# GENERAL register map
Vendor: Texas Instruments
Peripheral module from a debugger description file (folder omap36xx).
Registers are 32-bit, access per field, reset 0x0 unless marked. A register's access mark holds for its fields unless they carry their own. Offsets are as the file gives them; lines under a group give offsets from that group; [hi:lo] are bit positions; {n}, {i} and the like mark numbered series; 'fields as' and 'values as' point back to an identical list; <NAME> marks a mode.

## GENERAL
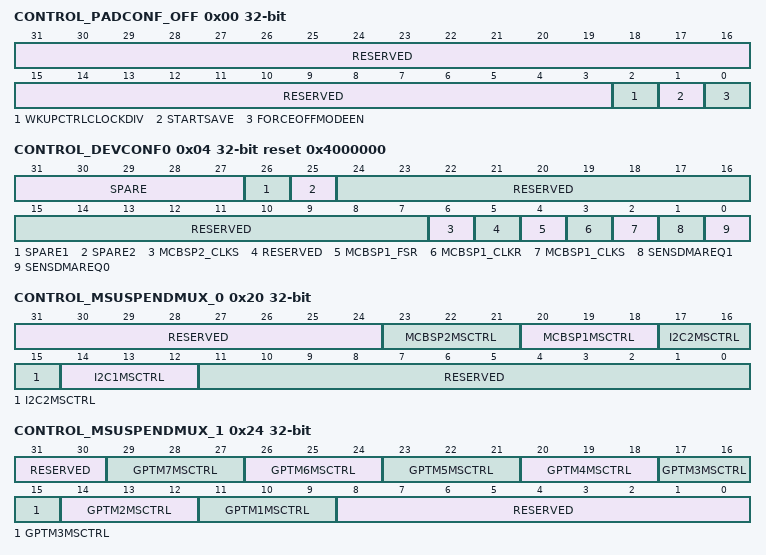
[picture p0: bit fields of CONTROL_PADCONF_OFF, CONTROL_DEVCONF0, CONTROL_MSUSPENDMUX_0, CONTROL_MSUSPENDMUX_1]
0x00 CONTROL_PADCONF_OFF — Off mode pad configuration register
  [31:3] RESERVED ro — Read returns reset value.
  [2] WKUPCTRLCLOCKDIV rw — Wkup_ctrl module clock divider0: Clock is divided by 4 1: Clock is divided by 2
  [1] STARTSAVE rw — Start pad configuration registers save mechanism
  [0] FORCEOFFMODEEN rw — Force OFF mode active
0x04 CONTROL_DEVCONF0 reset 0x4000000 — Static device configuration register-0. Module dedicated functions
  [31:27] SPARE rw — Spare bits
  [26] SPARE1 rw — Spare bit
  [25] SPARE2 rw — Spare bit
  [24:7] RESERVED ro — Read returns reset value
  [6] MCBSP2_CLKS rw — Select the CLKS input for the module McBSP2Note : There are no external pins McBSP2_CLKR and McBSP2_FSR for the module McBSP2. For this module, CLKR input is from the pin McBSP2_CLKX and FSR input is from the pin McBSP2_FSX .
  [5] RESERVED ro — Read returns reset value.
  [4] MCBSP1_FSR rw — Select the FSR input for the module McBSP1
  [3] MCBSP1_CLKR rw — Select the CLKR input for the module McBSP1
  [2] MCBSP1_CLKS rw — Select the CLKS input for the module McBSP1
  [1] SENSDMAREQ1 rw — Set sensitivity on SYS.DMAREQ1 input pin
  [0] SENSDMAREQ0 rw — Set sensitivity on SYS.DMAREQ0 input pin
0x20 CONTROL_MSUSPENDMUX_0 — MSuspend Control register: control the use of MSuspend signals at module level
  [31:24] RESERVED ro — Read returns reset value.
  [23:21] MCBSP2MSCTRL rw — Control McBSP_2 sensitivity to MCU and/or DSP MSuspend signals
  [20:18] MCBSP1MSCTRL rw — Control McBSP_1 sensitivity to MCU and/or DSP MSuspend signals
  [17:15] I2C2MSCTRL rw — Control I2C_2 sensitivity to MCU and/or DSP MSuspend signals
  [14:12] I2C1MSCTRL rw — Control I2C_1 sensitivity to MCU and/or DSP MSuspend signals
  [11:0] RESERVED ro — Read returns reset value.
0x24 CONTROL_MSUSPENDMUX_1 — MSuspend Control register : control the use of MSuspend signals at module level
  [31:30] RESERVED ro — Read returns reset value.
  [3n+8:3n+6] GPTM{n}MSCTRL rw (n=1..7) — Control General Purpose Timer {n} sensitivity to MCU and/or DSP MSuspend signals
  [8:0] RESERVED ro — Read returns reset value.
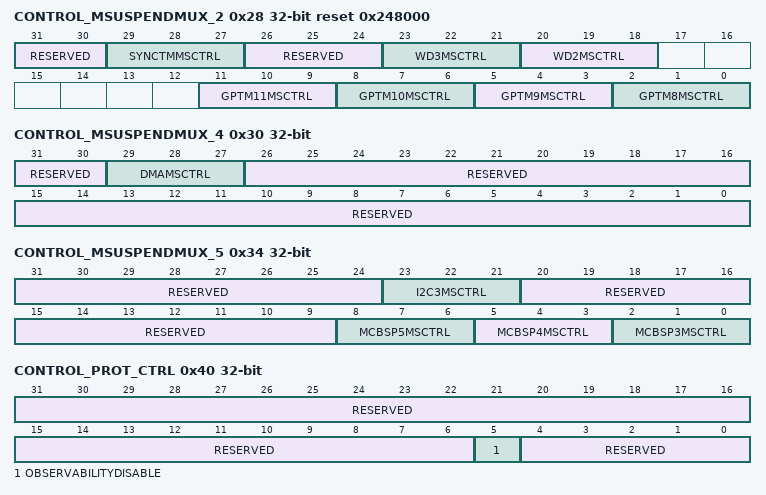
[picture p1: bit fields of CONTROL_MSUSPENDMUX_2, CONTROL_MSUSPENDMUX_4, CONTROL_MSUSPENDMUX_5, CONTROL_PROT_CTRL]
0x28 CONTROL_MSUSPENDMUX_2 reset 0x248000 — MSuspend Control register : control the use of MSuspend signals at module level
  [31:30] RESERVED ro — Read returns reset value.
  [29:27] SYNCTMMSCTRL rw — Control Sync Timer32K sensitivity to MCU and/or DSP MSuspend signals
  [26:24] RESERVED ro — Read returns reset value.
  [23:21] WD3MSCTRL rw — Control Watch Dog 3 sensitivity to MCU and/or DSP MSuspend signals
  [20:18] WD2MSCTRL rw — Control Watch Dog 2 sensitivity to MCU and/or DSP MSuspend signals
  [3n-22:3n-24] GPTM{n}MSCTRL rw (n=8..11) — Control General Purpose Timer {n} sensitivity to MCU and/or DSP MSuspend signals
0x2C CONTROL_MSUSPENDMUX_3 ro — MSuspend Control register : control the use of MSuspend signals at module level
  [31:0] RESERVED — Read returns reset value.
0x30 CONTROL_MSUSPENDMUX_4 — MSuspend Control register: control the use of MSuspend signals at module level
  [31:30] RESERVED ro — Read returns reset value.
  [29:27] DMAMSCTRL rw — Control DMA sensitivity to MCU and/or DSP MSuspend signals
  [26:0] RESERVED ro — Read returns reset value.
0x34 CONTROL_MSUSPENDMUX_5 — MSuspend Control register: control the use of MSuspend signals at module levelNot used
  [31:24] RESERVED ro — Read returns reset value.
  [23:21] I2C3MSCTRL rw — Control I2C-3 Sensitivity to MCU and/or DSP MSuspend Signals
  [20:9] RESERVED ro — Read returns reset value.
  [8:6] MCBSP5MSCTRL rw — Control McBSP-5 Sensitivity to MCU and/or DSP MSuspend Signals
  [5:3] MCBSP4MSCTRL rw — Control McBSP-4 Sensitivity to MCU and/or DSP MSuspend Signals
  [2:0] MCBSP3MSCTRL rw — Control McBSP-3 Sensitivity to MCU and/or DSP MSuspend Signals
0x40 CONTROL_PROT_CTRL access not given — control register
  [31:6] RESERVED ro — Read returns reset value.
  [5] OBSERVABILITYDISABLE — Control the observability feature (access R/OCO)
  [4:0] RESERVED ro — Read returns reset value.
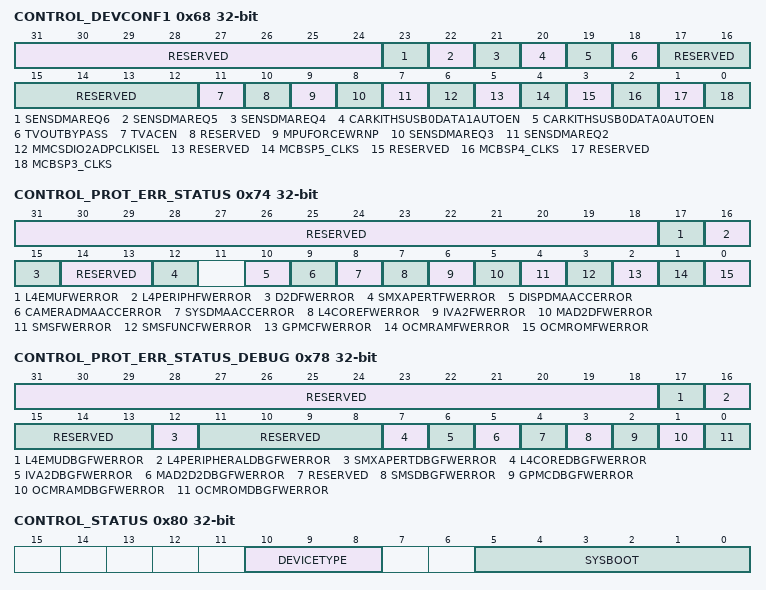
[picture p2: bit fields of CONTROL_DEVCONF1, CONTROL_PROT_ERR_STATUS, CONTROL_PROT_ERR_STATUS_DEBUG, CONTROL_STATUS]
0x68 CONTROL_DEVCONF1 — register description
  [31:24] RESERVED ro — Read returns reset value.
  [23] SENSDMAREQ6 rw — Set sensitivity on SYS.nDMAREQ6 input pin0 : Level sensitivity1 : Edge sensitivity
  [22] SENSDMAREQ5 rw — Set sensitivity on SYS.nDMAREQ5 input pin0 : Level sensitivity1 : Edge sensitivity
  [21] SENSDMAREQ4 rw — Set sensitivity on SYS.nDMAREQ4 input pin0 : Level sensitivity1 : Edge sensitivity
  [20] CARKITHSUSB0DATA1AUTOEN rw — Enable force from HSUB0 DATA1 pad configuration MuxMode when CARKITEN is generated:0: HSUB0 DATA1 pad MuxMode is driven by HSUB0 DATA1 pad configuration register.1: HSUB0 DATA1 pad MuxMode is forced to 0x2 when CARKITEN signal is active.
  [19] CARKITHSUSB0DATA0AUTOEN rw — Enable force from HSUB0 DATA0 pad configuration MuxMode when CARKITEN is generated0 : HSUB0 DATA0 pad MuxMode is driven by HSUB0 NXT pad configuration register1 : HSUB0 DATA0 pad MuxMode is forced to 0x2 when CARKITEN signal is active.
  [18] TVOUTBYPASS rw — Active high enable AVDAC TV out bypass
  [17:12] RESERVED ro — Read returns reset value.
  [11] TVACEN rw — TV AC coupled load enable0 : DC coupled load1 : AC coupled load
  [10] RESERVED ro — Read returns reset value.
  [9] MPUFORCEWRNP rw — Force MPU writes to be nonposted0 : Posted writes1 : Nonposted writes
  [8] SENSDMAREQ3 rw — Set sensitivity on SYS.nDMAREQ3 input pin0 : Level sensitivity1 : Edge sensitivity
  [7] SENSDMAREQ2 rw — Set sensitivity on SYS.nDMAREQ2 input pin0 : Level sensitivity1 : Edge sensitivity
  [6] MMCSDIO2ADPCLKISEL rw — MMC/SDIO2 Module Input Clock selection:0 : Input clock is from the external pin1 : Internal loop_back, module input clock is copied from the module output clock
  [5] RESERVED ro — Read returns reset value.
  [4] MCBSP5_CLKS rw — Select the CLKS input for the module McBSP50 : CLKS is from the PRCM functional clock1 : CLKS is from the external pin McBSP_CLKS
  [3] RESERVED ro — Read returns reset value.
  [2] MCBSP4_CLKS rw — Select the CLKS input for the module McBSP40 : CLKS is from the PRCM functional clock1 : CLKS is from the external pin McBSP_CLKS
  [1] RESERVED ro — Read returns reset value.
  [0] MCBSP3_CLKS rw — Select the CLKS input for the module McBSP30 : CLKS is from the PRCM functional clock1 : CLKS is from the external pin McBSP_CLKS
0x74 CONTROL_PROT_ERR_STATUS ro — Protection error status register
  [31:18] RESERVED — Read returns reset value.
  [17] L4EMUFWERROR — L4 Emulation Firewall Error
    0=No L4 Emulation interconnect firewall error; 1=L4 Emulation interconnect firewall error
  [16] L4PERIPHFWERROR — L4 Peripheral Firewall Error
    0=No L4 Peripheral interconnect firewall error; 1=L4 Peripheral interconnect firewall error
  [15] D2DFWERROR — D2D Firewalll error
    0=No D2D firewall error; 1=D2D firewall error
  [14:13] RESERVED — Read returns reset value.
  [12] SMXAPERTFWERROR — L3 Register target Firewall error
    0=No L3 Register Target firewall error; 1=L3 Register Target firewall error
  [10] DISPDMAACCERROR — Disp Dma Access Error
    0=No access error to DISP DMA protection channels; 1=Unauthorized access to a DISP DMA protection channel
  [9] CAMERADMAACCERROR — Camera Dma Access Error
    0=No access error to Camera DMA protection channels; 1=Unauthorized access to a Camera DMA protection channel
  [8] SYSDMAACCERROR — sDma Access Error
    0=No access error to sDMA protection channels; 1=Unauthorized access to a sDMA protection channel
  [7] L4COREFWERROR — L4 Protection Firewall Error
    0=No error from L4 Core protection firewall; 1=Error from L4 Core protection firewall
  [6] IVA2FWERROR — IVA2 Protection Firewall Error
    0=No error from IVA2 protection firewall; 1=Error from IVA2 protection firewall
  [5] MAD2DFWERROR — MAD2D Firewall Error
    0=No MAD2D functional firewall error; 0=No MAD2D functional firewall error
  [4] SMSFWERROR — SMS Firewall Error
    0=No SMS firewall error; 1=SMS firewall error
  [3] SMSFUNCFWERROR — SMS Functional Firewall Error
    0=No SMS functional firewall error; 1=SMS functional firewall error
  [2] GPMCFWERROR — GPMC Firewall Error
    0=No error from GPMC protection firewall; 1=Error from GPMC protection firewall
  [1] OCMRAMFWERROR — On Chip Ram Firewall Error
    0=No error from On Chip RAM protection firewall; 1=Error from On Chip RAM protectionfirewall
  [0] OCMROMFWERROR — On Chip Rom Firewall Error
    0=No error from On Chip ROM protection firewall; 1=Error from On Chip ROM protection firewall
0x78 CONTROL_PROT_ERR_STATUS_DEBUG ro — Protection Error Status Debug Register
  [31:18] RESERVED — Read returns reset value
  [17] L4EMUDBGFWERROR — L4 Emulation Debug Firewall Error
  [16] L4PERIPHERALDBGFWERROR — L4 Peripheral Debug Firewall Error
  [15:13] RESERVED — Read returns reset value
  [12] SMXAPERTDBGFWERROR — L3 Register target Debug Firewall error
  [11:8] RESERVED — Read returns reset value.
  [7] L4COREDBGFWERROR — L4 Core Debug Firewall Error
  [6] IVA2DBGFWERROR — IVA2 Debug Firewall Error
  [5] MAD2D2DBGFWERROR — MAD2D Debug Firewall Error
  [4] RESERVED — Read returns reset value.
  [3] SMSDBGFWERROR — SMS Debug Firewall Error
  [2] GPMCDBGFWERROR — GPMC Debug Firewall Error
  [1] OCMRAMDBGFWERROR — On Chip Ram Debug Firewall Error
  [0] OCMROMDBGFWERROR — On Chip Rom Debug Firewall Error
0x80 CONTROL_STATUS ro reset not defined — register description
  [10:8] DEVICETYPE — Device type value sampled at power_on reset0b011 : GP deviceOther values : Reserved
  [5:0] SYSBOOT — Sys.Boot pin values sampled at power_on reset
0x84 CONTROL_GENERAL_PURPOSE_STATUS ro — register description
  [0] SAVEDONE — Pad configuration save status:0 : Save is not completed1 : Save is completed
{0x90+4i} CONTROL_RPUB_KEY_H_{i} ro (i=0..4) — rpub_key_h_{i} register description
  [31:0] RPKH_{i} — Root_public_key_hash {i}
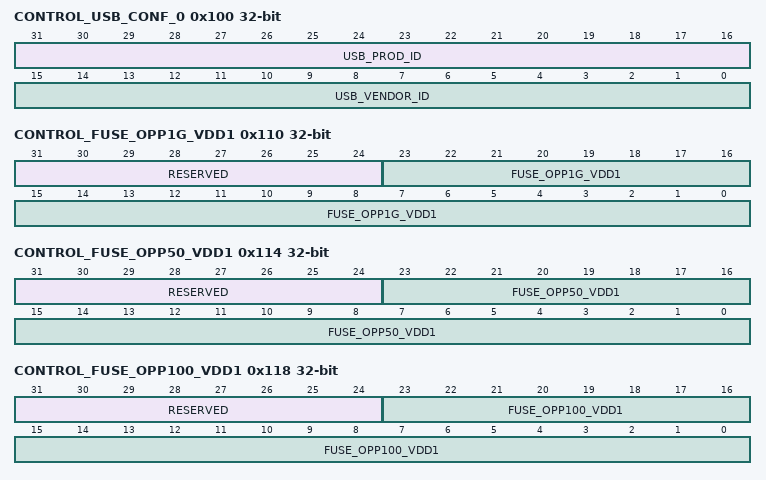
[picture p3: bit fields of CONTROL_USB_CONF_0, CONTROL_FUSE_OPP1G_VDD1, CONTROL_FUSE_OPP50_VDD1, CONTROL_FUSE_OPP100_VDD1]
0x100 CONTROL_USB_CONF_0 ro — usb_conf_0 register description
  [31:16] USB_PROD_ID — USB product ID
  [15:0] USB_VENDOR_ID — Vendor ID
0x104 CONTROL_USB_CONF_1 ro — usb_conf_1 register description
  [31:0] USB_CONF_1 — USB Fuse conf 1. SEQ_DISADAPTCLK (1), USB PHY detection mode(0).
0x110 CONTROL_FUSE_OPP1G_VDD1 ro (reset mask 0xFF000000) — Standard fuse OPP1G [23:0]
  [31:24] RESERVED — Read returns reset value.
  [23:0] FUSE_OPP1G_VDD1 — SmartReflex Ntarget value for OPP1GVDD1
0x114 CONTROL_FUSE_OPP50_VDD1 ro (reset mask 0xFF000000) — Standard fuse OPP50 [23:0]
  [31:24] RESERVED — Read returns reset value.
  [23:0] FUSE_OPP50_VDD1 — SmartReflex Ntarget value for OPP50VDD1
0x118 CONTROL_FUSE_OPP100_VDD1 ro (reset mask 0xFF000000) — Standard fuse OPP100 [23:0]
  [31:24] RESERVED — Read returns reset value.
  [23:0] FUSE_OPP100_VDD1 — SmartReflex Ntarget value for OPP100VDD1
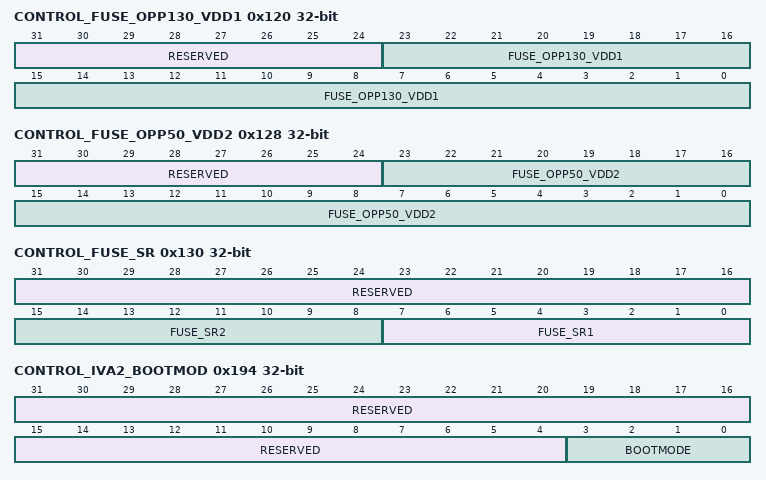
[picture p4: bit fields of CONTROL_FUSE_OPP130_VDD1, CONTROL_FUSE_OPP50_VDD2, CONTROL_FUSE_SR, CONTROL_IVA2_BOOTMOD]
0x120 CONTROL_FUSE_OPP130_VDD1 ro (reset mask 0xFF000000) — Standard fuse OPP130 [23:0]
  [31:24] RESERVED — Read returns reset value.
  [23:0] FUSE_OPP130_VDD1 — SmartReflex Ntarget value for OPP130VDD1
0x128 CONTROL_FUSE_OPP50_VDD2 ro (reset mask 0xFF000000) — Standard fuse OPP50 VDD2 [23:0]
  [31:24] RESERVED — Read returns reset value.
  [23:0] FUSE_OPP50_VDD2 — SmartReflex Ntarget value for OPP50 VDD2
0x130 CONTROL_FUSE_SR ro — Fuse SR1 and SR2
  [31:16] RESERVED — Read returns reset value.
  [15:8] FUSE_SR2
  [7:0] FUSE_SR1
0x190 CONTROL_IVA2_BOOTADDR — This register defines the physical address of the IVA2 boot loader
  [31:10] BOOTLOADADDR rw — Physical Address of the IVA2 boot loader. This is an index to a 4kByte page
0x194 CONTROL_IVA2_BOOTMOD — This register defines the IVA2 bootmode
  [31:4] RESERVED ro — Read returns reset value.
  [3:0] BOOTMODE rw — Boot mode of the IVA2
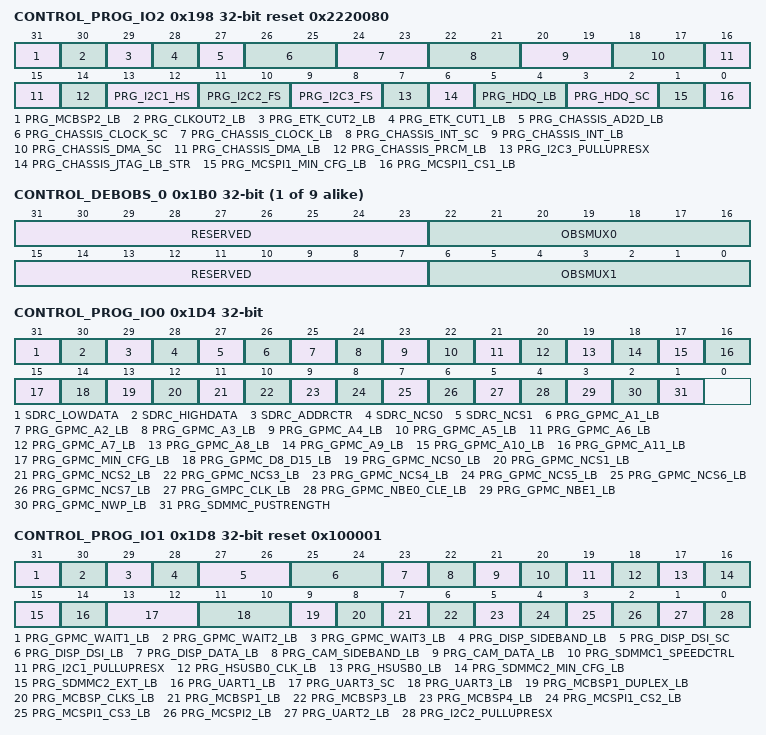
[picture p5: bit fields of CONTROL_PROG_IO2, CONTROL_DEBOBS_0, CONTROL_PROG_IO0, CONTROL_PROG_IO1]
0x198 CONTROL_PROG_IO2 rw reset 0x2220080 — prog_io2 register description
  [31] PRG_MCBSP2_LB — Format used in the field name below is : (programmable_group_name)_(configurable_pin on IO cell)Far end load setting.Transmission Line (TL) characteristic impedance is 50 Ohm, TL capacitance =1pF / cm : 0x0: Far end load = [1pF-10pF] / TL length=[1cm-6cm] 0x1: Far end load = [10pF-16pF] / TL length=[1cm-6cm]
  [30] PRG_CLKOUT2_LB — Format used in the field name below is : (programmable_group_name)_(configurable_pin on IO cell)Far end load setting.Transmission Line (TL) characteristic impedance is 50 Ohm, TL capacitance =1pF / cm : 0x0: Far end load = [1pF-10pF] / TL length=[1cm-6cm] 0x1: Far end load = [10pF-16pF] / TL length=[1cm-6cm]
  [29] PRG_ETK_CUT2_LB — Format used in the field name below is : (programmable_group_name)_(configurable_pin on IO cell)Far end load setting.Transmission Line (TL) characteristic impedance is 50 Ohm, TL capacitance =1pF / cm : 0x0: Far end load = [1pF-10pF] / TL length=[1cm-6cm] 0x1: Far end load = [10pF-16pF] / TL length=[1cm-6cm]
  [28] PRG_ETK_CUT1_LB — Format used in the field name below is : (programmable_group_name)_(configurable_pin on IO cell)Far end load setting.Transmission Line (TL) characteristic impedance is 50 Ohm, TL capacitance =1pF / cm : 0x0: Far end load = [1pF-10pF] / TL length=[1cm-6cm] 0x1: Far end load = [10pF-16pF] / TL length=[1cm-6cm]
  [27] PRG_CHASSIS_AD2D_LB — Format used in the field name below is : (programmable_group_name)_(configurable_pin on IO cell)Far end load setting.Transmission Line (TL) characteristic impedance is 50 Ohm, TL capacitance =1pF / cm : 0x0: Far end load = [1pF-10pF] / TL length=[1cm-6cm] 0x1: Far end load = [10pF-16pF] / TL length=[1cm-6cm]
  [26:25] PRG_CHASSIS_CLOCK_SC — Slew rate control bits.Format used in the field name below is: (programmable_group_name)_(configurable_pin on IO cell) See for the allowed SC vs LB bit field combinations
  [24:23] PRG_CHASSIS_CLOCK_LB — Effective TL length and farend capacitive load controls. This bit allows control of programmable drive/slew control on IO cell. Format used in the field name below is: (programmable_group_name)_(configurable_pin on IO cell)See for the allowed SC vs LB bit field combinations
  [22:21] PRG_CHASSIS_INT_SC — Slew rate control bits.Format used in the field name below is: (programmable_group_name)_(configurable_pin on IO cell) See for the allowed SC vs LB bit field combinations
  [20:19] PRG_CHASSIS_INT_LB — Effective TL length and farend capacitive load controls. This bit allows control of programmable drive/slew control on IO cell. Format used in the field name below is: (programmable_group_name)_(configurable_pin on IO cell)See for the allowed SC vs LB bit field combinations
  [18:17] PRG_CHASSIS_DMA_SC — Slew rate control bits.Format used in the field name below is: (programmable_group_name)_(configurable_pin on IO cell) See for the allowed SC vs LB bit field combinations
  [16:15] PRG_CHASSIS_DMA_LB — Effective TL length and farend capacitive load controls. This bit allows control of programmable drive/slew control on IO cell. Format used in the field name below is: (programmable_group_name)_(configurable_pin on IO cell)See for the allowed SC vs LB bit field combinations
  [14] PRG_CHASSIS_PRCM_LB — Format used in the field name below is : (programmable_group_name)_(configurable_pin on IO cell)Far end load setting.Transmission Line (TL) characteristic impedance is 50 Ohm, TL capacitance =1pF / cm: 0x0: Far end load = [1pF-10pF] / TL length=[1cm-6cm] 0x1: Far end load = [10pF-16pF] / TL length=[1cm-6cm]
  [13:12] PRG_I2C1_HS — The bits select a proper resistor value for the I2C1 pullups for a given load range at FS / HS modes.Format used in the field name below is: (programmable_group_name)_(configurable_pin on IO cell) FS mode :0b00: 4,5K Ohms / 5-15pF cap.load0b01: 2,1K Ohms /15-50pF cap.load0b10: 860 Ohms / 50-150pF cap.load0b11: Reserved HS mode :0b00: 1,66K Ohms / 5-12pF cap.load0b01: 920 Ohms / 12-25pF cap.load0b10: 500 Ohms/ 25-50pF cap.load0b11: 300 Ohms/ 50-80pF cap.load See for example [LB1:LB0] bit field vs PRG_I2C1_PULLUPRESX bit combinations.
  [11:10] PRG_I2C2_FS — The bits select a proper resistor value for the I2C2 pull-ups for a given load range at FS / HS modes.Format used in the field name below is : (programmable_group_name)_(configurable_pin on IO cell) FS mode :0b00: 4,5K Ohms / 5-15pF cap.load0b01: 2,1K Ohms /15-50pF cap.load0b10: 860 Ohms / 50-150pF cap.load0b11: Reserved HS mode :0b00: 1,66K Ohms / 5-12pF cap.load0b01: 920 Ohms / 12-25pF cap.load0b10: 500 Ohms/ 25-50pF cap.load0b11: 300 Ohms/ 50-80pF cap.load See for example [LB1:LB0] bit field vs PRG_I2C2_PULLUPRESX bit combinations.
  [9:8] PRG_I2C3_FS — The bits select a proper resistor value for the I2C3 pull-ups for a given load range at FS / HS modes.Format used in the field name below is : (programmable_group_name)_(configurable_pin on IO cell) FS mode :0b00: 4,5K Ohms / 5-15pF cap.load0b01: 2,1K Ohms /15-50pF cap.load0b10: 860 Ohms / 50-150pF cap.load0b11: Reserved HS mode :0b00: 1,66K Ohms / 5-12pF cap.load0b01: 920 Ohms / 12-25pF cap.load0b10: 500 Ohms/ 25-50pF cap.load0b11: 300 Ohms/ 50-80pF cap.load See for example [LB1:LB0] bit field vs PRG_I2C3_PULLUPRESX bit combinations.
  [7] PRG_I2C3_PULLUPRESX — Format used in the field name below is : (programmable_group_name)_(configurable_pin on IO cell)I2C3 pad group control for internal pull-up resistors enable:0x0 : Enables internal pull-ups for the I2C3 pad group0x1: Disables internal pull-ups for the I2C3 pad group
  [6] PRG_CHASSIS_JTAG_LB_STR — Format used in the field name below is : (programmable_group_name)_(configurable_pin on IO cell)Far end load setting.Transmission Line (TL) characteristic impedance is 50 Ohm, TL capacitance =1pF / cm: 0x0: Far end load = [1pF-10pF] / TL length=[1cm-6cm] 0x1: Far end load = [10pF-16pF] / TL length=[1cm-6cm]
  [5:4] PRG_HDQ_LB — Effective TL length and farend capacitive load controls. This bit allows control of programmable drive/slew control on IO cell. Format used in the field name below is: (programmable_group_name)_(configurable_pin on IO cell)See for the allowed SC vs LB bit field combinations !
  [3:2] PRG_HDQ_SC — Slew rate control bits.Format used in the field name below is : (programmable_group_name)_(configurable_pin on IO cell) See for the allowed SC vs LB bitfield combinations !
  [1] PRG_MCSPI1_MIN_CFG_LB — Format used in the field name below is : (programmable_group_name)_(configurable_pin on IO cell)Far end load setting.Transmission Line (TL) characteristic impedance is 50 Ohm, TL capacitance =1pF / cm: 0x0: Far end load = [1pF-10pF] / TL length=[1cm-6cm] 0x1: Far end load = [10pF-16pF] / TL length=[1cm-6cm]
  [0] PRG_MCSPI1_CS1_LB — Format used in the field name below is : (programmable_group_name)_(configurable_pin on IO cell)Far end load setting.Transmission Line (TL) characteristic impedance is 50 Ohm, TL capacitance =1pF / cm: 0x0: Far end load = [1pF-10pF] / TL length=[1cm-6cm] 0x1: Far end load = [10pF-16pF] / TL length=[1cm-6cm]
0x19C CONTROL_MEM_RTA_CTRL reset 0x1 — control_mem_rta_ctrl register description
  [0] HD_MEM_RTA_SEL rw — Device level control for selection of RTA feature of HD memories in the device1 : RTA enabled0 : RTA disabled
{0x1B0+4i} CONTROL_DEBOBS_{i} (i=0..8) — Select the set of signals to be observed for hw_dbg{2i}, hw_dbg{2i+1}
  [31:23] RESERVED ro — Read returns reset value.
  [22:16] OBSMUX{2i} rw — Select the set of signals to be exported for WKUPOBSMUX{2i}
  [15:7] RESERVED ro — Read returns reset value.
  [6:0] OBSMUX{2i+1} rw — Select the set of signals to be exported for WKUPOBSMUX{2i+1}
0x1D4 CONTROL_PROG_IO0 — prog_io0 register description
  [31] SDRC_LOWDATA rw — This bit allows for drive strength control on DDR output buffer for high speed operations. Format used in the field name below is : (programmable_group_name)_(configurable_pin on IO cell) Drive strength for output load: 0x0: Load range = [2 pF-4 pF] 0x1: Load range = [4 pF-12 pF]
  [30] SDRC_HIGHDATA rw — This bit allows for drive strength control on DDR output buffer for high speed operations. Format used in the field name below is : (programmable_group_name)_(configurable_pin on IO cell)Drive strength for output load: 0x0: Load range = [2 pF-4 pF] 0x1: Load range = [4 pF-12 pF]
  [29] SDRC_ADDRCTR rw — This bit allows for drive strength control on DDR output buffer for high speed operations. Format used in the field name below is : (programmable_group_name)_(configurable_pin on IO cell)Drive strength for output load: 0x0: Load range = [2 pF-4 pF] 0x1: Load range = [4 pF-12 pF]
  [28] SDRC_NCS0 rw — This bit allows for drive strength control on DDR output buffer for high speed operations. Format used in the field name below is : (programmable_group_name)_(configurable_pin on IO cell)Drive strength for output load: 0x0: Load range = [2 pF-4 pF] 0x1: Load range = [4 pF-12 pF]
  [27] SDRC_NCS1 rw — This bit allows for drive strength control on DDR output buffer for high speed operations. Format used in the field name below is : (programmable_group_name)_(configurable_pin on IO cell)Drive strength for output load: 0x0: Load range = [2 pF-4 pF] 0x1: Load range = [4 pF-12 pF]
  [27-n] PRG_GPMC_A{n}_LB rw (n=1..11) — Format used in the field name below is : (programmable_group_name)_(configurable_pin on IO cell)Far end load setting.Transmission Line (TL) characteristic impedance is 50 Ohm, TL capacitance =1pF / cm : 0x0: Far end load = [1pF-10pF] / TL length=[1cm-6cm] 0x1: Far end load = [10pF-16pF] / TL length=[1cm-6cm]
  [15] PRG_GPMC_MIN_CFG_LB rw — Format used in the field name below is : (programmable_group_name)_(configurable_pin on IO cell)Far end load setting.Transmission Line (TL) characteristic impedance is 50 Ohm, TL capacitance =1pF / cm : 0x0: Far end load = [1pF-10pF] / TL length=[1cm-6cm] 0x1: Far end load = [10pF-16pF] / TL length=[1cm-6cm]
  [14] PRG_GPMC_D8_D15_LB rw — Format used in the field name below is : (programmable_group_name)_(configurable_pin on IO cell)Far end load setting.Transmission Line (TL) characteristic impedance is 50 Ohm, TL capacitance =1pF / cm : 0x0: Far end load = [1pF-10pF] / TL length=[1cm-6cm] 0x1: Far end load = [10pF-16pF] / TL length=[1cm-6cm]
  [13-n] PRG_GPMC_NCS{n}_LB rw (n=0..7) — Format used in the field name below is : (programmable_group_name)_(configurable_pin on IO cell)Far end load setting.Transmission Line (TL) characteristic impedance is 50 Ohm, TL capacitance =1pF / cm : 0x0: Far end load = [1pF-10pF] / TL length=[1cm-6cm] 0x1: Far end load = [10pF-16pF] / TL length=[1cm-6cm]
  [5] PRG_GMPC_CLK_LB rw — Format used in the field name below is : (programmable_group_name)_(configurable_pin on IO cell)Far end load setting.Transmission Line (TL) characteristic impedance is 50 Ohm, TL capacitance =1pF / cm : 0x0: Far end load = [1pF-10pF] / TL length=[1cm-6cm] 0x1: Far end load = [10pF-16pF] / TL length=[1cm-6cm]
  [4] PRG_GPMC_NBE0_CLE_LB rw — Format used in the field name below is : (programmable_group_name)_(configurable_pin on IO cell)Far end load setting.Transmission Line (TL) characteristic impedance is 50 Ohm, TL capacitance =1pF / cm : 0x0: Far end load = [1pF-10pF] / TL length=[1cm-6cm] 0x1: Far end load = [10pF-16pF] / TL length=[1cm-6cm]
  [3] PRG_GPMC_NBE1_LB rw — Format used in the field name below is : (programmable_group_name)_(configurable_pin on IO cell)Far end load setting.Transmission Line (TL) characteristic impedance is 50 Ohm, TL capacitance =1pF / cm : 0x0: Far end load = [1pF-10pF] / TL length=[1cm-6cm] 0x1: Far end load = [10pF-16pF] / TL length=[1cm-6cm]
  [2] PRG_GPMC_NWP_LB rw — Format used in the field name below is : (programmable_group_name)_(configurable_pin on IO cell)Far end load setting.Transmission Line (TL) characteristic impedance is 50 Ohm, TL capacitance =1pF / cm : 0x0: Far end load = [1pF-10pF] / TL length=[1cm-6cm] 0x1: Far end load = [10pF-16pF] / TL length=[1cm-6cm]
  [1] PRG_SDMMC_PUSTRENGTH rw — This bit allows control of programmable pullup strength on SDMMC IO cells. Format used in the field name below is : (programmable_group_name)_(configurable_pin on IO cell)Conducting pullup with : 0x0: 50–110 kΩ strength selected 0x1: 10–50 kΩ strength selected
0x1D8 CONTROL_PROG_IO1 rw reset 0x100001 — prog_io1 register description
  [31] PRG_GPMC_WAIT1_LB — Format used in the field name below is : (programmable_group_name)_(configurable_pin on IO cell)Far end load setting.Transmission Line (TL) characteristic impedance is 50 Ohm, TL capacitance =1pF / cm : 0x0: Far end load = [1pF-10pF] / TL length=[1cm-6cm] 0x1: Far end load = [10pF-16pF] / TL length=[1cm-6cm]
  [30] PRG_GPMC_WAIT2_LB — Format used in the field name below is : (programmable_group_name)_(configurable_pin on IO cell)Far end load setting.Transmission Line (TL) characteristic impedance is 50 Ohm, TL capacitance =1pF / cm : 0x0: Far end load = [1pF-10pF] / TL length=[1cm-6cm] 0x1: Far end load = [10pF-16pF] / TL length=[1cm-6cm]
  [29] PRG_GPMC_WAIT3_LB — Format used in the field name below is : (programmable_group_name)_(configurable_pin on IO cell)Far end load setting.Transmission Line (TL) characteristic impedance is 50 Ohm, TL capacitance =1pF / cm : 0x0: Far end load = [1pF-10pF] / TL length=[1cm-6cm] 0x1: Far end load = [10pF-16pF] / TL length=[1cm-6cm]
  [28] PRG_DISP_SIDEBAND_LB — Format used in the field name below is : (programmable_group_name)_(configurable_pin on IO cell)Far end load setting.Transmission Line (TL) characteristic impedance is 50 Ohm, TL capacitance =1pF / cm : 0x0: Far end load = [1pF-10pF] / TL length=[1cm-6cm] 0x1: Far end load = [10pF-16pF] / TL length=[1cm-6cm]
  [27:26] PRG_DISP_DSI_SC — Slew rate control bits.Format used in the field name below is : (programmable_group_name)_(configurable_pin on IO cell) See for the allowed SC vs LB bitfield combinations !
  [25:24] PRG_DISP_DSI_LB — Effective TL length and farend capacitive load controls. This bit allows control of programmable drive/slew control on IO cell. Format used in the field name below is : (programmable_group_name)_(configurable_pin on IO cell)See for the allowed SC vs LB bitfield combinations !
  [23] PRG_DISP_DATA_LB — Format used in the field name below is : (programmable_group_name)_(configurable_pin on IO cell)Far end load setting.Transmission Line (TL) characteristic impedance is 50 Ohm, TL capacitance =1pF / cm : 0x0: Far end load = [1pF-10pF] / TL length=[1cm-6cm] 0x1: Far end load = [10pF-16pF] / TL length=[1cm-6cm]
  [22] PRG_CAM_SIDEBAND_LB — Format used in the field name below is : (programmable_group_name)_(configurable_pin on IO cell)Far end load setting.Transmission Line (TL) characteristic impedance is 50 Ohm, TL capacitance =1pF / cm : 0x0: Far end load = [1pF-10pF] / TL length=[1cm-6cm] 0x1: Far end load = [10pF-16pF] / TL length=[1cm-6cm]
  [21] PRG_CAM_DATA_LB — Format used in the field name below is : (programmable_group_name)_(configurable_pin on IO cell)Far end load setting.Transmission Line (TL) characteristic impedance is 50 Ohm, TL capacitance =1pF / cm : 0x0: Far end load = [1pF-10pF] / TL length=[1cm-6cm] 0x1: Far end load = [10pF-16pF] / TL length=[1cm-6cm]
  [20] PRG_SDMMC1_SPEEDCTRL — Speed Control for MMC I/O0b0 : 26 MHz I/O max speed . 0b1 : 52 MHz I/O max speed .
  [19] PRG_I2C1_PULLUPRESX — Format used in the field name below is : (programmable_group_name)_(configurable_pin on IO cell)I2C1 pad group control for internal pull-up resistors enable:0x0 : Enables internal pull-ups for the I2C1 pad group0x1: Disables internal pull-ups for the I2C1 pad group
  [18] PRG_HSUSB0_CLK_LB — Format used in the field name below is : (programmable_group_name)_(configurable_pin on IO cell)Far end load setting.Transmission Line (TL) characteristic impedance is 50 Ohm, TL capacitance =1pF / cm : 0x0: Far end load = [1pF-10pF] / TL length=[1cm-6cm] 0x1: Far end load = [10pF-16pF] / TL length=[1cm-6cm]
  [17] PRG_HSUSB0_LB — Format used in the field name below is : (programmable_group_name)_(configurable_pin on IO cell)Far end load setting.Transmission Line (TL) characteristic impedance is 50 Ohm, TL capacitance =1pF / cm : 0x0: Far end load = [1pF-10pF] / TL length=[1cm-6cm] 0x1: Far end load = [10pF-16pF] / TL length=[1cm-6cm]
  [16] PRG_SDMMC2_MIN_CFG_LB — Format used in the field name below is : (programmable_group_name)_(configurable_pin on IO cell)Far end load setting.Transmission Line (TL) characteristic impedance is 50 Ohm, TL capacitance =1pF / cm : 0x0: Far end load = [1pF-10pF] / TL length=[1cm-6cm] 0x1: Far end load = [10pF-16pF] / TL length=[1cm-6cm]
  [15] PRG_SDMMC2_EXT_LB — Format used in the field name below is : (programmable_group_name)_(configurable_pin on IO cell)Far end load setting.Transmission Line (TL) characteristic impedance is 50 Ohm, TL capacitance =1pF / cm : 0x0: Far end load = [1pF-10pF] / TL length=[1cm-6cm] 0x1: Far end load = [10pF-16pF] / TL length=[1cm-6cm]
  [14] PRG_UART1_LB — Format used in the field name below is : (programmable_group_name)_(configurable_pin on IO cell)Far end load setting.Transmission Line (TL) characteristic impedance is 50 Ohm, TL capacitance =1pF / cm : 0x0: Far end load = [1pF-10pF] / TL length=[1cm-6cm] 0x1: Far end load = [10pF-16pF] / TL length=[1cm-6cm]
  [13:12] PRG_UART3_SC — Slew rate control bits.Format used in the field name below is : (programmable_group_name)_(configurable_pin on IO cell) See for the allowed SC vs LB bitfield combinations !
  [11:10] PRG_UART3_LB — Effective TL length and farend capacitive load controls. This bit allows control of programmable drive/slew control on IO cell. Format used in the field name below is : (programmable_group_name)_(configurable_pin on IO cell)See for the allowed SC vs LB bitfield combinations !
  [9] PRG_MCBSP1_DUPLEX_LB — Format used in the field name below is : (programmable_group_name)_(configurable_pin on IO cell)Far end load setting.Transmission Line (TL) characteristic impedance is 50 Ohm, TL capacitance =1pF / cm : 0x0: Far end load = [1pF-10pF] / TL length=[1cm-6cm] 0x1: Far end load = [10pF-16pF] / TL length=[1cm-6cm]
  [8] PRG_MCBSP_CLKS_LB — Format used in the field name below is : (programmable_group_name)_(configurable_pin on IO cell)Far end load setting.Transmission Line (TL) characteristic impedance is 50 Ohm, TL capacitance =1pF / cm : 0x0: Far end load = [1pF-10pF] / TL length=[1cm-6cm] 0x1: Far end load = [10pF-16pF] / TL length=[1cm-6cm]
  [7] PRG_MCBSP1_LB — Format used in the field name below is : (programmable_group_name)_(configurable_pin on IO cell)Far end load setting.Transmission Line (TL) characteristic impedance is 50 Ohm, TL capacitance =1pF / cm : 0x0: Far end load = [1pF-10pF] / TL length=[1cm-6cm] 0x1: Far end load = [10pF-16pF] / TL length=[1cm-6cm]
  [6] PRG_MCBSP3_LB — Format used in the field name below is : (programmable_group_name)_(configurable_pin on IO cell)Far end load setting.Transmission Line (TL) characteristic impedance is 50 Ohm, TL capacitance =1pF / cm : 0x0: Far end load = [1pF-10pF] / TL length=[1cm-6cm] 0x1: Far end load = [10pF-16pF] / TL length=[1cm-6cm]
  [5] PRG_MCBSP4_LB — Format used in the field name below is : (programmable_group_name)_(configurable_pin on IO cell)Far end load setting.Transmission Line (TL) characteristic impedance is 50 Ohm, TL capacitance =1pF / cm : 0x0: Far end load = [1pF-10pF] / TL length=[1cm-6cm] 0x1: Far end load = [10pF-16pF] / TL length=[1cm-6cm]
  [4] PRG_MCSPI1_CS2_LB — Format used in the field name below is : (programmable_group_name)_(configurable_pin on IO cell)Far end load setting.Transmission Line (TL) characteristic impedance is 50 Ohm, TL capacitance =1pF / cm : 0x0: Far end load = [1pF-10pF] / TL length=[1cm-6cm] 0x1: Far end load = [10pF-16pF] / TL length=[1cm-6cm]
  [3] PRG_MCSPI1_CS3_LB — Format used in the field name below is : (programmable_group_name)_(configurable_pin on IO cell)Far end load setting.Transmission Line (TL) characteristic impedance is 50 Ohm, TL capacitance =1pF / cm : 0x0: Far end load = [1pF-10pF] / TL length=[1cm-6cm] 0x1: Far end load = [10pF-16pF] / TL length=[1cm-6cm]
  [2] PRG_MCSPI2_LB — Format used in the field name below is : (programmable_group_name)_(configurable_pin on IO cell)Far end load setting.Transmission Line (TL) characteristic impedance is 50 Ohm, TL capacitance =1pF / cm : 0x0: Far end load = [1pF-10pF] / TL length=[1cm-6cm] 0x1: Far end load = [10pF-16pF] / TL length=[1cm-6cm]
  [1] PRG_UART2_LB — Format used in the field name below is : (programmable_group_name)_(configurable_pin on IO cell)Far end load setting.Transmission Line (TL) characteristic impedance is 50 Ohm, TL capacitance =1pF / cm : 0x0: Far end load = [1pF-10pF] / TL length=[1cm-6cm] 0x1: Far end load = [10pF-16pF] / TL length=[1cm-6cm]
  [0] PRG_I2C2_PULLUPRESX — Format used in the field name below is : (programmable_group_name)_(configurable_pin on IO cell)I2C2 pad group control for internal pull-up resistors enable:0x0 : Enables internal pull-ups for the I2C2 pad group0x1: Disables internal pull-ups for the I2C2 pad group
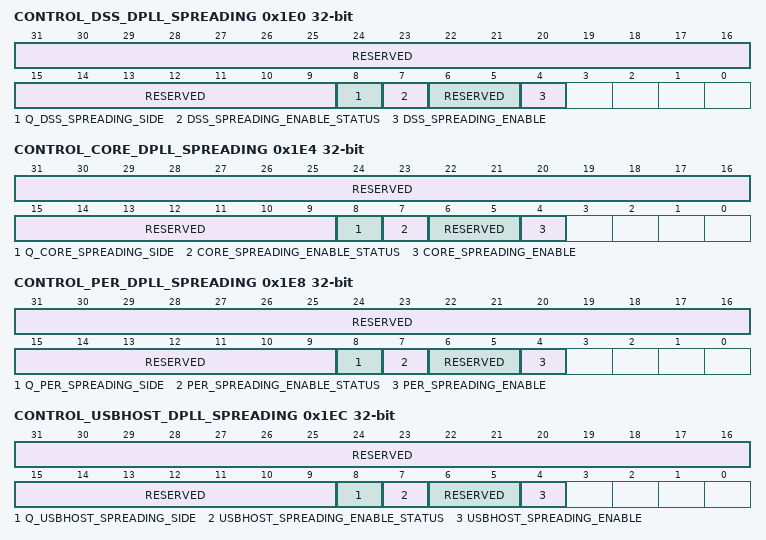
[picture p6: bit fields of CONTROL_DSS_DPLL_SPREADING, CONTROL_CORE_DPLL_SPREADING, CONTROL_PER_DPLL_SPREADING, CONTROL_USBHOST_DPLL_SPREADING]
0x1E0 CONTROL_DSS_DPLL_SPREADING (reset mask 0xFFFFFF7F) — control_dss_dpll_spreading register description
  [31:9] RESERVED ro — Read returns reset value
  [8] Q_DSS_SPREADING_SIDE rw — 0 : Enables both side frequency spread about the programmed frequency1 : Enables low frequency spread only
  [7] DSS_SPREADING_ENABLE_STATUS ro — Indicates the status of the SSC feature
  [6:5] RESERVED ro — Read returns reset value
  [4] DSS_SPREADING_ENABLE rw — Enables/disables EMI reduction feature (spreading):0: Modulation stops at the end of the current modulation cycle. 1: Modulation cycle is started.
0x1E4 CONTROL_CORE_DPLL_SPREADING (reset mask 0xFFFFFF7F) — control_core_dpll_spreading register description
  [31:9] RESERVED ro — Read returns reset value.
  [8] Q_CORE_SPREADING_SIDE rw — 0 : Enables both side frequency spread about the programmed frequency1 : Enables low frequency spread only
  [7] CORE_SPREADING_ENABLE_STATUS ro — Indicates the status of the SSC feature
  [6:5] RESERVED ro — Read returns reset value
  [4] CORE_SPREADING_ENABLE rw — Enables/disables EMI reduction feature (spreading):0: Modulation stops at the end of the current modulation cycle. 1: Modulation cycle is started.
0x1E8 CONTROL_PER_DPLL_SPREADING (reset mask 0xFFFFFF7F) — control_per_dpll_spreading register description
  [31:9] RESERVED ro — Read returns reset value
  [8] Q_PER_SPREADING_SIDE rw — 0 : Enables both side frequency spread about the programmed frequency1 : Enables low frequency spread only
  [7] PER_SPREADING_ENABLE_STATUS ro — Indicates the status of the SSC feature.
  [6:5] RESERVED ro — Read returns reset value
  [4] PER_SPREADING_ENABLE rw — Enables/disables EMI reduction feature (spreading): 0: Modulation stops at the end of the current modulation cycle. 1: Modulation cycle is started.
0x1EC CONTROL_USBHOST_DPLL_SPREADING (reset mask 0xFFFFFF7F) — control_usbhost_dpll_spreading register description
  [31:9] RESERVED ro — Read returns reset value.
  [8] Q_USBHOST_SPREADING_SIDE rw — 0 : Enables both side frequency spread about the programmed frequency1 : Enables low frequency spread only
  [7] USBHOST_SPREADING_ENABLE_STATUS ro — Indicates the status of the SSC feature.
  [6:5] RESERVED ro — Read returns reset value
  [4] USBHOST_SPREADING_ENABLE rw — Enables/disables EMI reduction feature (spreading):0: Modulation stops at the end of the current modulation cycle. 1: Modulation cycle is started.
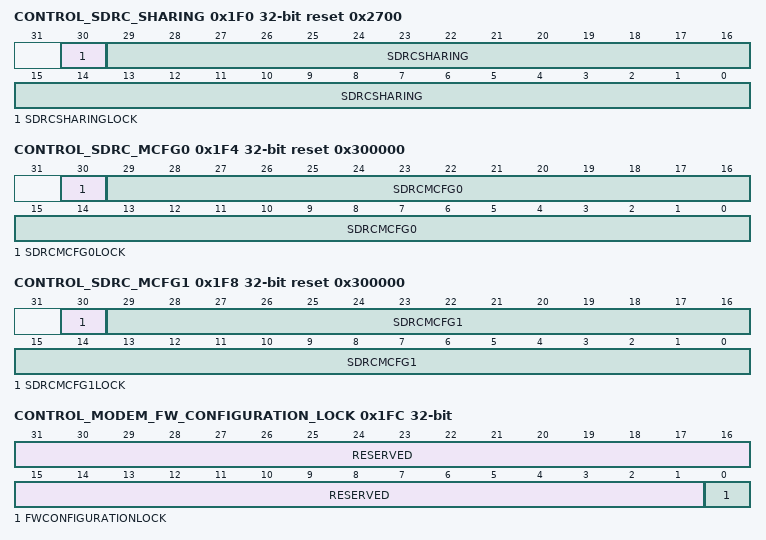
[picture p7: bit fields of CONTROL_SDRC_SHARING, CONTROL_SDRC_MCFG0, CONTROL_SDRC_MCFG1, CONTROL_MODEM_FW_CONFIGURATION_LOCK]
0x1F0 CONTROL_SDRC_SHARING access not given reset 0x2700 — SDRC Sharing configuration register
  [30] SDRCSHARINGLOCK rw — Exported value to SDRC.SDRC_SHARING[30]For more information, see ,
  [29:0] SDRCSHARING rw — Exported value to SDRC.SDRC_SHARING[29:0]For more information, see ,
0x1F4 CONTROL_SDRC_MCFG0 access not given reset 0x300000 — SDRC MCFG Configuration register-0
  [30] SDRCMCFG0LOCK rw — Exported value to SDRC.SDRC_MCFG_0[30]For more information, see ,
  [29:0] SDRCMCFG0 rw — Exported value to SDRC.SDRC_MCFG_0[29:0]For more information, see ,
0x1F8 CONTROL_SDRC_MCFG1 access not given reset 0x300000 — SDRC MCFG Configuration register-1
  [30] SDRCMCFG1LOCK rw — Exported value to SDRC.SDRC_MCFG_1[30]For more information, see ,
  [29:0] SDRCMCFG1 rw — Exported value to SDRC.SDRC_MCFG_1[29:0]For more information, see ,
0x1FC CONTROL_MODEM_FW_CONFIGURATION_LOCK access not given — Allows locking of the modem isolation registers in the SCM until the next battery removal.
  [31:1] RESERVED ro — Read returns reset value.
  [0] FWCONFIGURATIONLOCK — Allows locking of the modem isolation registers in the SCM until the next battery removal. (access See)
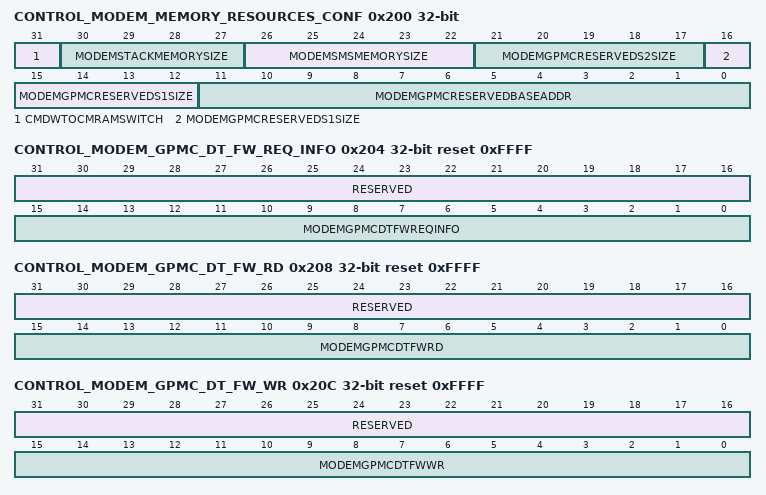
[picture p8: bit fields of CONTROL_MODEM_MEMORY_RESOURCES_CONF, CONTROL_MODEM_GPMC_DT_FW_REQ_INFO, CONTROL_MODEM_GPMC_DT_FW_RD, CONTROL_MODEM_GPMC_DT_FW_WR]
0x200 CONTROL_MODEM_MEMORY_RESOURCES_CONF access not given — Modem Memory Resources Conf
  [31] CMDWTOCMRAMSWITCH — Select if CMDWT or OCMRAM is accessible by the Modem (access See)
  [30:27] MODEMSTACKMEMORYSIZE — Configuration of the modem stack memory size (access See)
  [26:22] MODEMSMSMEMORYSIZE — Configuration of the SMS modem memory (access See)
  [21:17] MODEMGPMCRESERVEDS2SIZE — Configuration of the GPMC modem shared section size (access See)
  [16:12] MODEMGPMCRESERVEDS1SIZE — Configuration of the GPMC modem reserved section size (access See)
  [11:0] MODEMGPMCRESERVEDBASEADDR — Configuration of the GPMC base address of the modem reserved section. This base address is configurable in 1Mbyte step. (access See)
0x204 CONTROL_MODEM_GPMC_DT_FW_REQ_INFO access not given reset 0xFFFF — Modem GPMC Default firewall request info register
  [31:16] RESERVED ro — Read returns reset value.
  [15:0] MODEMGPMCDTFWREQINFO — Exported values to the GPMC firewall region1 REQ_INFO_PERMISSION field (access See)
0x208 CONTROL_MODEM_GPMC_DT_FW_RD access not given reset 0xFFFF — Modem GPMC Default firewall read permission register
  [31:16] RESERVED ro — Read returns reset value.
  [15:0] MODEMGPMCDTFWRD — Exported values to the GPMC firewall region1 READ_PERMISSION field (access See)
0x20C CONTROL_MODEM_GPMC_DT_FW_WR access not given reset 0xFFFF — Modem GPMC Default firewall write permission register
  [31:16] RESERVED ro — Read returns reset value.
  [15:0] MODEMGPMCDTFWWR — Exported values to the GPMC firewall region1 WRITE_PERMISSION field (access See)
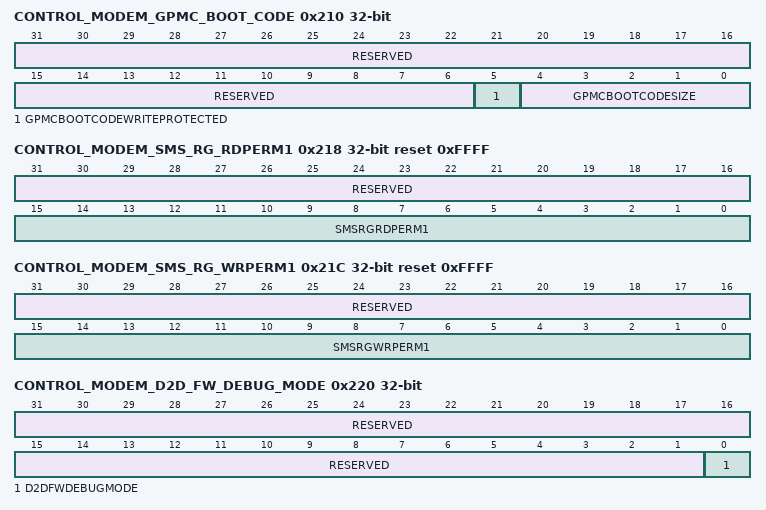
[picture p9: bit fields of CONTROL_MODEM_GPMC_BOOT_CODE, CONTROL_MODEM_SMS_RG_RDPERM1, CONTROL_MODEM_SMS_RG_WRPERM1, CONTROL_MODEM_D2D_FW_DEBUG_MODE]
0x210 CONTROL_MODEM_GPMC_BOOT_CODE access not given — GPMC Flash Boot Code protection register
  [31:6] RESERVED ro — Read returns reset value.
  [5] GPMCBOOTCODEWRITEPROTECTED — When set HIGH the Flash Boot Code area is write protected (access See)
  [4:0] GPMCBOOTCODESIZE — Size of the Flash boot code to protect (access See)
0x214 CONTROL_MODEM_SMS_RG_ATT1 access not given reset 0xFFFFFFFF — Modem SMS Default firewall register
  [31:0] SMSRGATT1 — Exported values to the SMS firewall region1 SMS_RG_ATT1 field (access See)
0x218 CONTROL_MODEM_SMS_RG_RDPERM1 access not given reset 0xFFFF — Modem SMS Default firewall read permission register
  [31:16] RESERVED ro — Read returns reset value.
  [15:0] SMSRGRDPERM1 — Exported values to the SMS firewall region1 SMS_RG_RDPERM1 field (access See)
0x21C CONTROL_MODEM_SMS_RG_WRPERM1 access not given reset 0xFFFF — Modem SMS Default firewall write permission register
  [31:16] RESERVED ro — Read returns reset value.
  [15:0] SMSRGWRPERM1 — Exported values to the SMS firewall region1 SMS_RG_WRPERM1 field (access See)
0x220 CONTROL_MODEM_D2D_FW_DEBUG_MODE access not given — D2D firewall debug mode register
  [31:1] RESERVED ro — Read returns reset value.
  [0] D2DFWDEBUGMODE — When set to high the L3-D2D FW is in debug mode. (access See)
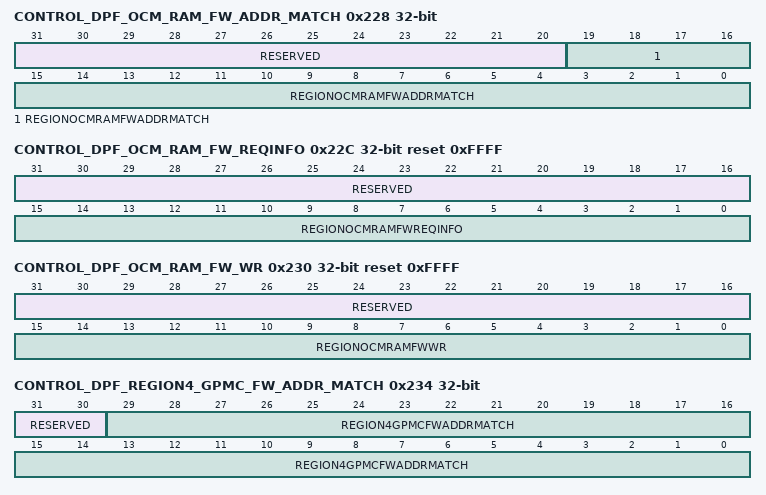
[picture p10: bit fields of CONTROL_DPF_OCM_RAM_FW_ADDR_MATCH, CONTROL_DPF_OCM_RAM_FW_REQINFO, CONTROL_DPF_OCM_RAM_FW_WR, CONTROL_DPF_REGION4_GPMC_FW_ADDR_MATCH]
0x228 CONTROL_DPF_OCM_RAM_FW_ADDR_MATCH ro — OCM RAM Dynamic Power Framework Handing
  [31:20] RESERVED — Read returns reset value
  [19:0] REGIONOCMRAMFWADDRMATCH — See L3 FW addr_match field
0x22C CONTROL_DPF_OCM_RAM_FW_REQINFO ro reset 0xFFFF — OCM RAM Dynamic Power Framework Handing
  [31:16] RESERVED — Read returns reset value
  [15:0] REGIONOCMRAMFWREQINFO — See L3 FW REQINFO permission field
0x230 CONTROL_DPF_OCM_RAM_FW_WR ro reset 0xFFFF — OCM RAM Dynamic Power Framework Handing
  [31:16] RESERVED — Read returns reset value
  [15:0] REGIONOCMRAMFWWR — See L3 FW WR permission field
0x234 CONTROL_DPF_REGION4_GPMC_FW_ADDR_MATCH ro — GPMC Dynamic Power Framework Handing
  [31:30] RESERVED — Read returns reset value
  [29:0] REGION4GPMCFWADDRMATCH — Exported value to L3 FW region 4 GPMC ADDR_MATCH4 field
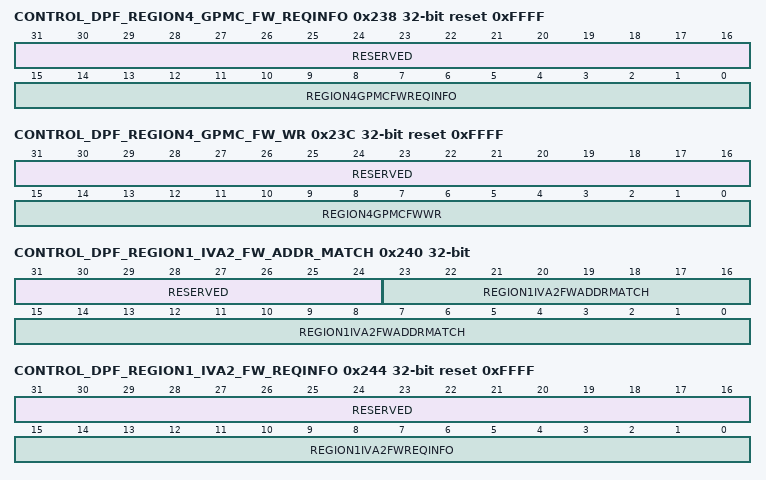
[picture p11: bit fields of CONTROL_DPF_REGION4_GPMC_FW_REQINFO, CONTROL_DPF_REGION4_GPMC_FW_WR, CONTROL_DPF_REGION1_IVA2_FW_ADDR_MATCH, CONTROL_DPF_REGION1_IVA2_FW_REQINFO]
0x238 CONTROL_DPF_REGION4_GPMC_FW_REQINFO ro reset 0xFFFF — GPMC Dynamic Power Framework Handing
  [31:16] RESERVED — Read returns reset value.
  [15:0] REGION4GPMCFWREQINFO — Exported value to L3 FW region 4 GPMC REQINFO_PERMISSION_4 field
0x23C CONTROL_DPF_REGION4_GPMC_FW_WR ro reset 0xFFFF — GPMC Dynamic Power Framework Handing
  [31:16] RESERVED — Read returns reset value.
  [15:0] REGION4GPMCFWWR — Exported value to L3 FW region 4 GPMC WRITE_PERMISSION_4 field
0x240 CONTROL_DPF_REGION1_IVA2_FW_ADDR_MATCH ro — IVA2 Dynamic Power Framework Handing
  [31:24] RESERVED — Read returns reset value
  [23:0] REGION1IVA2FWADDRMATCH — Exported value to L3 FW region 1 IVA2 ADDR_MATCH1 field
0x244 CONTROL_DPF_REGION1_IVA2_FW_REQINFO ro reset 0xFFFF — IVA2 Dynamic Power Framework Handing
  [31:16] RESERVED — Read returns reset value.
  [15:0] REGION1IVA2FWREQINFO — Exported value to L3 FW region 1 IVA2 REQINFO_PERMISSION_1 field
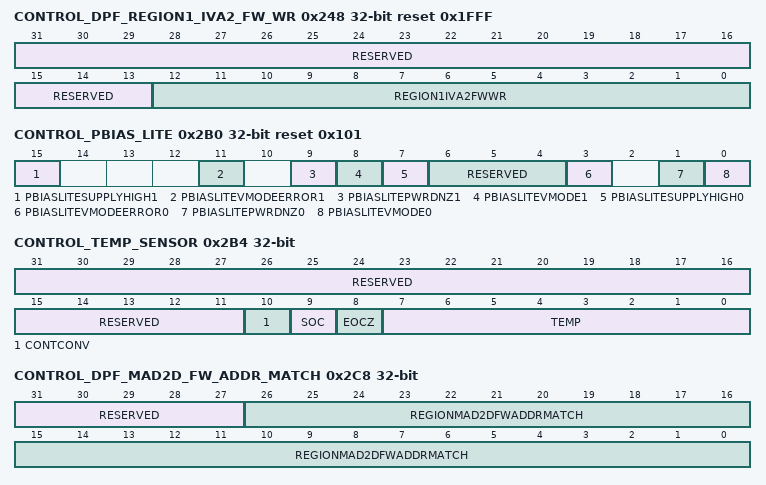
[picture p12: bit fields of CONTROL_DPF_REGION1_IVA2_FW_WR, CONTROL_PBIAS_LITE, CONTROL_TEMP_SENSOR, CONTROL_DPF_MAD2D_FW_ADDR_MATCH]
0x248 CONTROL_DPF_REGION1_IVA2_FW_WR ro reset 0x1FFF — IVA2 Dynamic Power Framework Handing
  [31:13] RESERVED — Read returns reset value.
  [12:0] REGION1IVA2FWWR — Exported value to L3 FW region 1 IVA2 WRITE_PERMISSION_1 field
0x2B0 CONTROL_PBIAS_LITE reset 0x101 — This register controls the settings for PBIAS LITE MMC/SD/SDIO1 pins
  [15] PBIASLITESUPPLYHIGH1 ro — Status indicating if PBIAS1 cell is supplied by 1.8 or 3.0 SIM_VDDS 1 =&gt; SIM_VDDS = 3.0 V 0 =&gt; SIM_VDDS = 1.8 V
  [11] PBIASLITEVMODEERROR1 ro — Status indicating if the software-programmed VMODE level matches the SUPPLY_HI output signal0b0 =&gt; VMODE Level same or VMODE level not considered.0b1 =&gt; indicates VMODE_LEVEL not same as SUPPLY_HI_OUT
  [9] PBIASLITEPWRDNZ1 rw — Input signal referenced to VDD2. Software must keep this signal low whenever SIM_VDDS is ramping up. 1 =&gt; SIM_VDDS stable 0 =&gt; SIM_VDDS is ramping up
  [8] PBIASLITEVMODE1 rw — SIM_VDDS voltage level information:1 =&gt; SIM_VDDS = 3.0 V 0 =&gt; SIM_VDDS = 1.8 V
  [7] PBIASLITESUPPLYHIGH0 ro — Status indicating if PBIAS0 is supplied by 1.8 V or 3.0 V SDMMC1_VDDS0b0 => PBIAS0 is supplied by SDMMC1_VDDS = 1.8 V . 0b1 => PBIAS0 is supplied by SDMMC1_VDDS = 3.0 V .
  [6:4] RESERVED ro — Read returns reset value.
  [3] PBIASLITEVMODEERROR0 ro — Status indicating if the software programmed VMODE level matches the SUPPLY_HI output signal0b0 => VMODE level same or VMODE level not considered . 0b1 => Indicates VMODE_LEVEL not same as SUPPLY_HI_OUT .
  [1] PBIASLITEPWRDNZ0 rw — Input Signal Referenced to VDD2. Software has to keep this bit at 0b0 when SDMMC1_VDDS is ramping up0b0 => SDMMC1_VDDS ramping up . 0b1 => SDMMC1_VDDS stable .
  [0] PBIASLITEVMODE0 rw — SDMMC1_VDDS voltage level information control from software0b0 => SDMMC1_VDDS = 1.8 V . 0b1 => SDMMC1_VDDS = 3.0 V .
0x2B4 CONTROL_TEMP_SENSOR — temperature sensor register
  [31:11] RESERVED ro — Read returns reset value.
  [10] CONTCONV rw — VDD level digital inputs. When high the ADC is in continuous conversion mode0 : ADC Single Conversion Mode;1 : ADC Continuous Conversion Mode
  [9] SOC rw — ADC Start of Conversion. A transition to high starts a new ADC conversion cycle
  [8] EOCZ ro — ADC End of Conversion. Active low, when CTRL_ TEMP[7:0] is valid
  [7:0] TEMP ro — Temperature data from the ADC. Valid if EOCZ is low
0x2C8 CONTROL_DPF_MAD2D_FW_ADDR_MATCH ro — MAD2D Dynamic Power Framework Handing
  [31:27] RESERVED — Read returns reset value
  [26:0] REGIONMAD2DFWADDRMATCH — See L3 FW addr match field
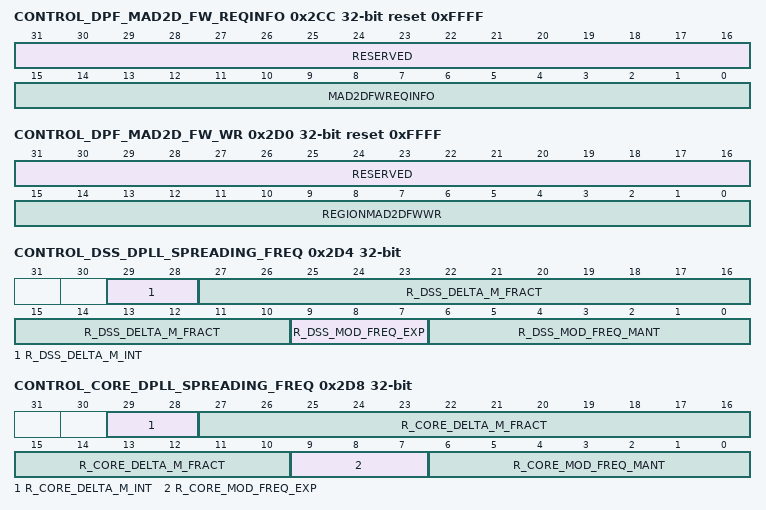
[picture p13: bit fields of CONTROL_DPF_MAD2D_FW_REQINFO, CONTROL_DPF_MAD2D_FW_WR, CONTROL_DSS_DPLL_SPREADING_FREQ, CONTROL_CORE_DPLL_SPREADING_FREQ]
0x2CC CONTROL_DPF_MAD2D_FW_REQINFO ro reset 0xFFFF — MAD2D Dynamic Power Framework Handing
  [31:16] RESERVED — Read returns reset value
  [15:0] MAD2DFWREQINFO — See L3 FW REQINFO permission field
0x2D0 CONTROL_DPF_MAD2D_FW_WR ro reset 0xFFFF — MAD2D Dynamic Power Framework Handing
  [31:16] RESERVED — Read returns reset value
  [15:0] REGIONMAD2DFWWR — See L3 FW WR permission field
0x2D4 CONTROL_DSS_DPLL_SPREADING_FREQ — control_dss_dpll_spreading_freq register description
  [29:28] R_DSS_DELTA_M_INT rw — Integer part of DeltaM coefficient
  [27:10] R_DSS_DELTA_M_FRACT rw — Fractional part of DeltaM coefficient
  [9:7] R_DSS_MOD_FREQ_EXP rw — Exponent of ModFreqDivider coefficient
  [6:0] R_DSS_MOD_FREQ_MANT rw — Mantissa of ModFreqDivider coefficient
0x2D8 CONTROL_CORE_DPLL_SPREADING_FREQ — control_core_dpll_spreading_freq register description
  [29:28] R_CORE_DELTA_M_INT rw — Integer part of DeltaM coefficient
  [27:10] R_CORE_DELTA_M_FRACT rw — Fractional part of DeltaM coefficient
  [9:7] R_CORE_MOD_FREQ_EXP rw — Exponent of ModFreqDivider coefficient
  [6:0] R_CORE_MOD_FREQ_MANT rw — Mantissa of ModFreqDivider coefficient
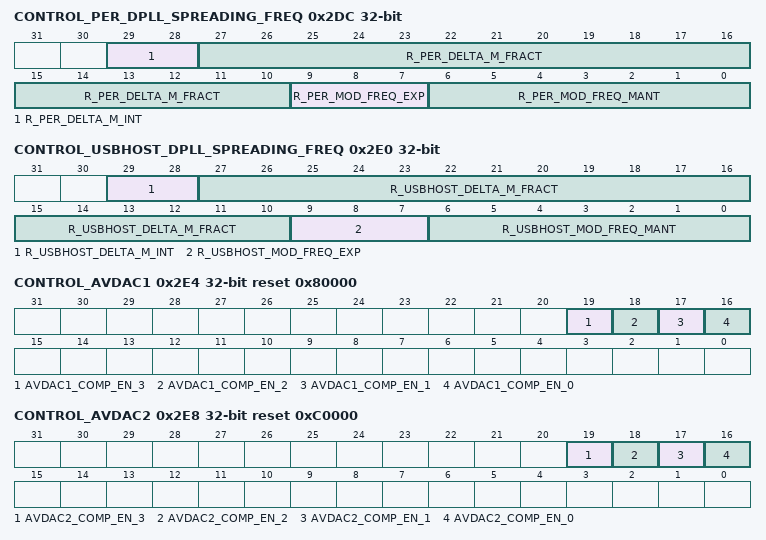
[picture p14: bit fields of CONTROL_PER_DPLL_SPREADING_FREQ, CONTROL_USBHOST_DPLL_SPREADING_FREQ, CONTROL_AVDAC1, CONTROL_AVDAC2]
0x2DC CONTROL_PER_DPLL_SPREADING_FREQ — control_per_dpll_spreading_freq register description
  [29:28] R_PER_DELTA_M_INT rw — Integer part of DeltaM coefficient
  [27:10] R_PER_DELTA_M_FRACT rw — Fractional part of DeltaM coefficient
  [9:7] R_PER_MOD_FREQ_EXP rw — Exponent of ModFreqDivider coefficient
  [6:0] R_PER_MOD_FREQ_MANT rw — Mantissa of ModFreqDivider coefficient
0x2E0 CONTROL_USBHOST_DPLL_SPREADING_FREQ — control_usbhost_dpll_spreading_freq register description
  [29:28] R_USBHOST_DELTA_M_INT rw — Integer part of DeltaM coefficient
  [27:10] R_USBHOST_DELTA_M_FRACT rw — Fractional part of DeltaM coefficient
  [9:7] R_USBHOST_MOD_FREQ_EXP rw — Exponent of ModFreqDivider coefficient
  [6:0] R_USBHOST_MOD_FREQ_MANT rw — Mantissa of ModFreqDivider coefficient
0x2E4 CONTROL_AVDAC1 access not given reset 0x80000 — control_avdac1 register description
  [19] AVDAC1_COMP_EN_3 rw — Optional control used only for dual-channel configuration. It should be low by default (single-channel configuration).
    0=(default) Single channel; 1=Dual channel configuration
  [18] AVDAC1_COMP_EN_2 rw — Optional control used only for dual-channel configuration. It should be low by default (single-channel configuration).
    0=(default) Module configured as Luma video channel (dual-channel configuration) or Composite video channel (single-channel configuration); 1=Module configured as Chroma video channel (dual-channel configuration)
  [17] AVDAC1_COMP_EN_1 rw — Optional control for lower output swing. It should be low by default (high output swing).
    0=(default) High full-scale output swing; 1=Low full-scale output swing
  [16] AVDAC1_COMP_EN_0 rw — Optional control for internal current reference. It should be low by default (external current reference).
    0=(default) External current reference (external resistor connected to rset); 1=Internal current reference. In this case, clkres clock is required to generate the current reference based on an internal switched-cap resistor.
0x2E8 CONTROL_AVDAC2 access not given reset 0xC0000 — control_avdac2 register description
  [19] AVDAC2_COMP_EN_3 rw — Optional control used only for dual-channel configuration. It should be low by default (single-channel configuration).
    0=(default) Single channel; 1=Dual channel configuration
  [18] AVDAC2_COMP_EN_2 rw — Optional control used only for dual-channel configuration. It should be low by default (single-channel configuration).
    values as CONTROL_AVDAC1.AVDAC1_COMP_EN_2
  [17] AVDAC2_COMP_EN_1 rw — Optional control for lower output swing. It should be low by default (high output swing).
    values as CONTROL_AVDAC1.AVDAC1_COMP_EN_1
  [16] AVDAC2_COMP_EN_0 rw — Optional control for internal current reference. It should be low by default (external current reference).
    values as CONTROL_AVDAC1.AVDAC1_COMP_EN_0
0x2F0 CONTROL_CAMERA_PHY_CTRL — Register to control the mode and multiplexing of the two camera complex IOs (CSIPHY2 and CSIPHY1 )
  [4] R_CONTROL_CSI1_RX_SEL rw — Selects the CAMERA PHY that will feed the receiver B on ISP2P 0 : CAMERA1_PHY data is sent to ISP2P receiver B 1 : CAMERA2_PHY data is sent to ISP2P receiver B
  [3:2] R_CONTROL_CAMERA1_PHY_CAMMODE rw — Sets the mode of CSIPHY100: D-PHY mode01: CCP2 mode configured for data/strobe transmission10: CCP2 mode configured for data/clock transmission11: GPI modeNot a dynamic signal. Should be changed only when the CSIPHY1 is in OFF power state
  [1:0] R_CONTROL_CAMERA2_PHY_CAMMODE rw — Sets the mode of CSIPHY200: D-PHY mode01: CCP2 mode configured for data/strobe transmission10: CCP2 mode configured for data/clock transmission11: GPI modeNot a dynamic signal. Should be changed only when the CSIPHY2 is in OFF power state
0x307F94 CONTROL_IDCODE ro reset 0x2F (reset mask 0xFFF) — Device IDCODE
  [31:28] VERSION — Revision number
  [27:12] HAWKEYE — Hawkeye number
  [11:1] TI_IDM — Manufacturer identity (TI)
  [0] _8211 — Always set to 1
